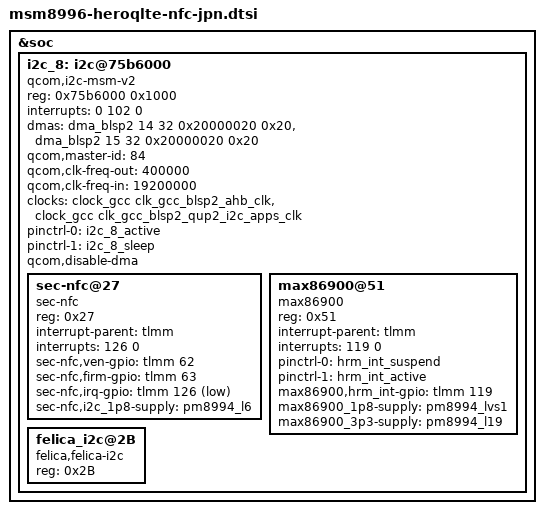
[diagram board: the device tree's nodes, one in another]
/* Copyright (c) 2013, Samsung Electronics Corporation. All rights reserved.
 *
 * This program is free software; you can redistribute it and/or modify
 * it under the terms of the GNU General Public License version 2 and
 * only version 2 as published by the Free Software Foundation.
 *
 * This program is distributed in the hope that it will be useful,
 * but WITHOUT ANY WARRANTY; without even the implied warranty of
 * MERCHANTABILITY or FITNESS FOR A PARTICULAR PURPOSE.  See the
 * GNU General Public License for more details.
 */

&soc {

	/* NFC */
	/delete-node/  i2c@75b6000;
	i2c_8: i2c@75b6000 { /* BLSP2 QUP1 */
		status = "okay";

		compatible = "qcom,i2c-msm-v2";
		#address-cells = <1>;
		#size-cells = <0>;
		reg-names = "qup_phys_addr";
		reg = <0x75b6000 0x1000>;
		interrupt-names = "qup_irq";
		interrupts = <0 102 0>;
		dmas = <&dma_blsp2 14 32 0x20000020 0x20>,
			<&dma_blsp2 15 32 0x20000020 0x20>;
		dma-names = "tx", "rx";
		qcom,master-id = <84>;
		qcom,clk-freq-out = <400000>;
		qcom,clk-freq-in  = <19200000>;
		clock-names = "iface_clk", "core_clk";
		clocks = <&clock_gcc clk_gcc_blsp2_ahb_clk>,
			<&clock_gcc clk_gcc_blsp2_qup2_i2c_apps_clk>;
		pinctrl-names = "i2c_active", "i2c_sleep";
		pinctrl-0 = <&i2c_8_active>;
		pinctrl-1 = <&i2c_8_sleep>;
		qcom,disable-dma;

		sec-nfc@27 {
			compatible = "sec-nfc";
			reg = <0x27>;
			interrupt-parent = <&tlmm>;
			interrupts = <126 0>;
			sec-nfc,ven-gpio = <&tlmm 62 0x0>;
			sec-nfc,firm-gpio = <&tlmm 63 0x0>;
			sec-nfc,irq-gpio = <&tlmm 126 0x01>;
			sec-nfc,i2c_1p8-supply = <&pm8994_l6>;
		};

		max86900@51 {
			compatible = "max86900";
			reg = <0x51>;
			interrupt-parent = <&tlmm>;
			interrupts = <119 0>;
			pinctrl-names = "sleep", "idle";
			pinctrl-0 = <&hrm_int_suspend>;
			pinctrl-1 = <&hrm_int_active>;
			max86900,hrm_int-gpio = <&tlmm 119 0x00>;
			max86900_1p8-supply = <&pm8994_lvs1>;
			max86900_3p3-supply = <&pm8994_l19>;
		};

		/delete-node/ i2c@2B;
		felica_i2c@2B {
			compatible = "felica,felica-i2c";
			reg = <0x2B>;
		};
	};

};
